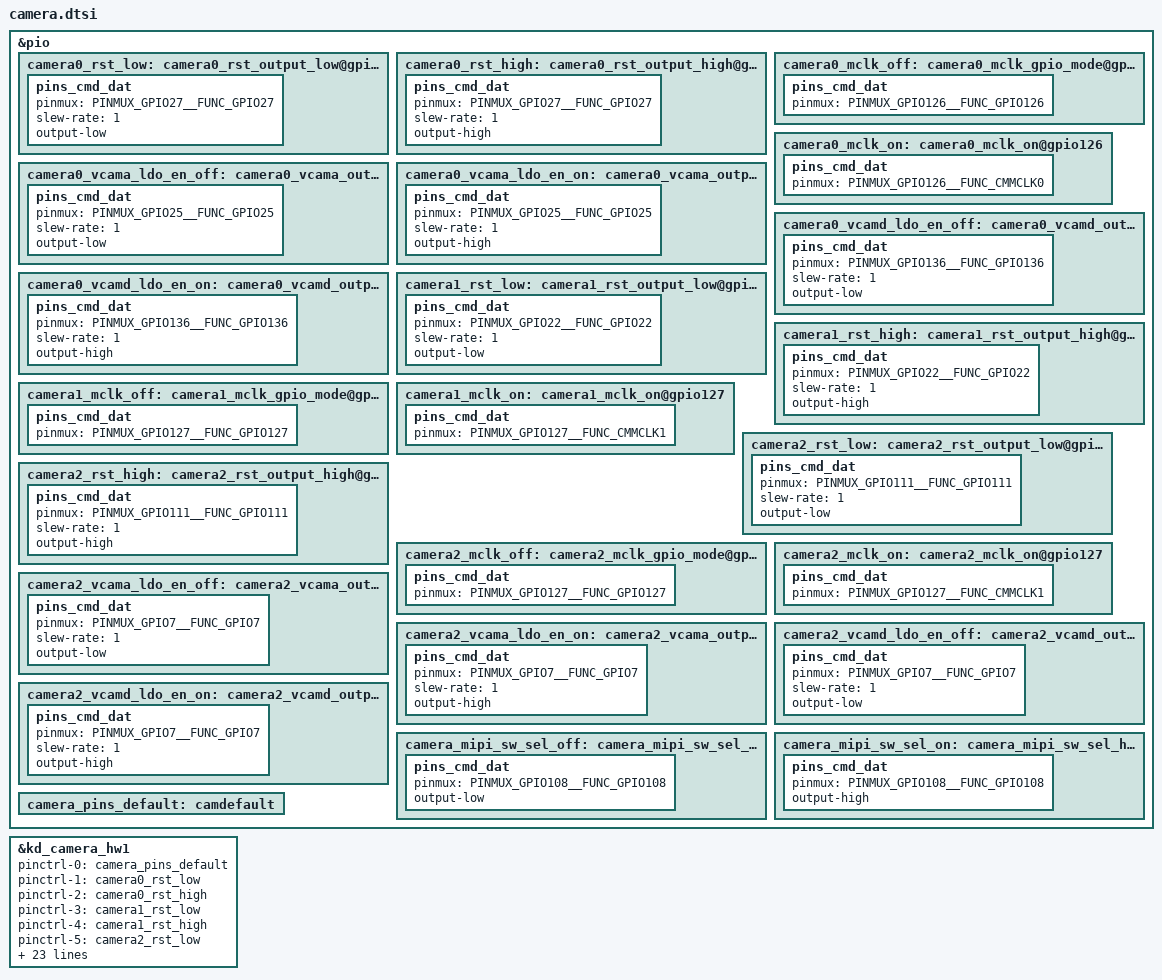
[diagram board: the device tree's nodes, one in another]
/*
 * Copyright (c) 2020 MediaTek Inc.
 *
 * This program is free software; you can redistribute it and/or modify
 * it under the terms of the GNU General Public License version 2 as
 * published by the Free Software Foundation.
 *
 * This program is distributed in the hope that it will be useful,
 * but WITHOUT ANY WARRANTY; without even the implied warranty of
 * MERCHANTABILITY or FITNESS FOR A PARTICULAR PURPOSE.  See the
 * GNU General Public License for more details.
 */

/*************  A02 Bringup Board  *************
 *    SW          :   HW   : Sensor
 * camera0(Rear)  : RCAM1  : IMX258
 * camera1(Front) : FCAM   : GC5035
 * camera2(Macro) : RCAM2  : GC02M1
 **********************************************/

/* CAMERA GPIO standardization */
&pio {
	/***************  Camera0  ***************/
	// Reset
	camera0_rst_low: camera0_rst_output_low@gpio27 {
		pins_cmd_dat {
			pinmux = <PINMUX_GPIO27__FUNC_GPIO27>;
			slew-rate = <1>;
			output-low;
		};
	};
	camera0_rst_high: camera0_rst_output_high@gpio27 {
		pins_cmd_dat {
			pinmux = <PINMUX_GPIO27__FUNC_GPIO27>;
			slew-rate = <1>;
			output-high;
		};
	};

	// MCLK
	camera0_mclk_off: camera0_mclk_gpio_mode@gpio126 {
		pins_cmd_dat {
			pinmux = <PINMUX_GPIO126__FUNC_GPIO126>;
		};
	};
	camera0_mclk_on: camera0_mclk_on@gpio126 {
		pins_cmd_dat {
			pinmux = <PINMUX_GPIO126__FUNC_CMMCLK0>;
		};
	};

	// AVDD
	camera0_vcama_ldo_en_off: camera0_vcama_output_low@gpio25 {
		pins_cmd_dat {
			pinmux = <PINMUX_GPIO25__FUNC_GPIO25>;
			slew-rate = <1>;
			output-low;
		};
	};
	camera0_vcama_ldo_en_on: camera0_vcama_output_high@gpio25 {
		pins_cmd_dat {
			pinmux = <PINMUX_GPIO25__FUNC_GPIO25>;
			slew-rate = <1>;
			output-high;
		};
	};

	// DVDD
	camera0_vcamd_ldo_en_off: camera0_vcamd_output_low@gpio136 {
		pins_cmd_dat {
			pinmux = <PINMUX_GPIO136__FUNC_GPIO136>;
			slew-rate = <1>;
			output-low;
		};
	};
	camera0_vcamd_ldo_en_on: camera0_vcamd_output_high@gpio136 {
		pins_cmd_dat {
			pinmux = <PINMUX_GPIO136__FUNC_GPIO136>;
			slew-rate = <1>;
			output-high;
		};
	};

	/***************  Camera1  ***************/
	// Reset
	camera1_rst_low: camera1_rst_output_low@gpio22 {
		pins_cmd_dat {
			pinmux = <PINMUX_GPIO22__FUNC_GPIO22>;
			slew-rate = <1>;
			output-low;
		};
	};
	camera1_rst_high: camera1_rst_output_high@gpio22 {
		pins_cmd_dat {
			pinmux = <PINMUX_GPIO22__FUNC_GPIO22>;
			slew-rate = <1>;
			output-high;
		};
	};

	// MCLK
	camera1_mclk_off: camera1_mclk_gpio_mode@gpio127 {
		pins_cmd_dat {
			pinmux = <PINMUX_GPIO127__FUNC_GPIO127>;
		};
	};
	camera1_mclk_on: camera1_mclk_on@gpio127 {
		pins_cmd_dat {
			pinmux = <PINMUX_GPIO127__FUNC_CMMCLK1>;
		};
	};

	/***************  Camera2  ***************/
	// Reset
	camera2_rst_low: camera2_rst_output_low@gpio111 {
		pins_cmd_dat {
			pinmux = <PINMUX_GPIO111__FUNC_GPIO111>;
			slew-rate = <1>;
			output-low;
		};
	};
	camera2_rst_high: camera2_rst_output_high@gpio111 {
		pins_cmd_dat {
			pinmux = <PINMUX_GPIO111__FUNC_GPIO111>;
			slew-rate = <1>;
			output-high;
		};
	};

	// MCLK
	camera2_mclk_off: camera2_mclk_gpio_mode@gpio127 {
		pins_cmd_dat {
			pinmux = <PINMUX_GPIO127__FUNC_GPIO127>;
		};
	};
	camera2_mclk_on: camera2_mclk_on@gpio127 {
		pins_cmd_dat {
			pinmux = <PINMUX_GPIO127__FUNC_CMMCLK1>;
		};
	};

	// AVDD
	camera2_vcama_ldo_en_off: camera2_vcama_output_low@gpio7 {
		pins_cmd_dat {
			pinmux = <PINMUX_GPIO7__FUNC_GPIO7>;
			slew-rate = <1>;
			output-low;
		};
	};
	camera2_vcama_ldo_en_on: camera2_vcama_output_high@gpio7 {
		pins_cmd_dat {
			pinmux = <PINMUX_GPIO7__FUNC_GPIO7>;
			slew-rate = <1>;
			output-high;
		};
	};

	// DVDD
	camera2_vcamd_ldo_en_off: camera2_vcamd_output_low@gpio7 {
		pins_cmd_dat {
			pinmux = <PINMUX_GPIO7__FUNC_GPIO7>;
			slew-rate = <1>;
			output-low;
		};
	};
	camera2_vcamd_ldo_en_on: camera2_vcamd_output_high@gpio7 {
		pins_cmd_dat {
			pinmux = <PINMUX_GPIO7__FUNC_GPIO7>;
			slew-rate = <1>;
			output-high;
		};
	};

	// MIPI Switch
	camera_mipi_sw_sel_off: camera_mipi_sw_sel_low@gpio108 {
		pins_cmd_dat {
			pinmux = <PINMUX_GPIO108__FUNC_GPIO108>;
			output-low;
		};
	};
	camera_mipi_sw_sel_on: camera_mipi_sw_sel_high@gpio108 {
		pins_cmd_dat {
			pinmux = <PINMUX_GPIO108__FUNC_GPIO108>;
			output-high;
		};
	};

	camera_pins_default: camdefault {
	};
};

&kd_camera_hw1 {
	pinctrl-names = "default",
			"cam0_rst0", "cam0_rst1",
			"cam1_rst0", "cam1_rst1",
			"cam2_rst0", "cam2_rst1",
			"cam0_mclk_off", "cam0_mclk_on",
			"cam1_mclk_off", "cam1_mclk_on",
			"cam2_mclk_off", "cam2_mclk_on",
			"cam0_vcama_off", "cam0_vcama_on",
			"cam0_vcamd_off", "cam0_vcamd_on",
			"cam2_vcama_off", "cam2_vcama_on",
			"cam2_vcamd_off", "cam2_vcamd_on",
			"cam_mipi_switch_sel_1",
			"cam_mipi_switch_sel_0";

	pinctrl-0 = <&camera_pins_default>;
	pinctrl-1 = <&camera0_rst_low>;
	pinctrl-2 = <&camera0_rst_high>;
	pinctrl-3 = <&camera1_rst_low>;
	pinctrl-4 = <&camera1_rst_high>;
	pinctrl-5 = <&camera2_rst_low>;
	pinctrl-6 = <&camera2_rst_high>;
	pinctrl-7 = <&camera0_mclk_off>;
	pinctrl-8 = <&camera0_mclk_on>;
	pinctrl-9 = <&camera1_mclk_off>;
	pinctrl-10 = <&camera1_mclk_on>;
	pinctrl-11 = <&camera2_mclk_off>;
	pinctrl-12 = <&camera2_mclk_on>;
	pinctrl-13 = <&camera0_vcama_ldo_en_off>;
	pinctrl-14 = <&camera0_vcama_ldo_en_on>;
	pinctrl-15 = <&camera0_vcamd_ldo_en_off>;
	pinctrl-16 = <&camera0_vcamd_ldo_en_on>;
	pinctrl-17 = <&camera2_vcama_ldo_en_off>;
	pinctrl-18 = <&camera2_vcama_ldo_en_on>;
	pinctrl-19 = <&camera2_vcamd_ldo_en_off>;
	pinctrl-20 = <&camera2_vcamd_ldo_en_on>;
	pinctrl-21 = <&camera_mipi_sw_sel_on>;
	pinctrl-22 = <&camera_mipi_sw_sel_off>;

	/********** Regulator setting **********/
	// Camera0
	cam0_vcamio-supply = <&mt_pmic_vcamio_ldo_reg>;
	cam0_vcamaf-supply = <&mt_pmic_vldo28_ldo_reg>;

	// Camera1
	cam1_vcama-supply = <&mt_pmic_vcama_ldo_reg>;
	cam1_vcamd-supply = <&mt_pmic_vcamd_ldo_reg>;
	cam1_vcamio-supply = <&mt_pmic_vcamio_ldo_reg>;

    // Camera2
	cam2_vcamio-supply = <&mt_pmic_vcamio_ldo_reg>;

	status = "okay";
};
/* CAMERA GPIO end */
